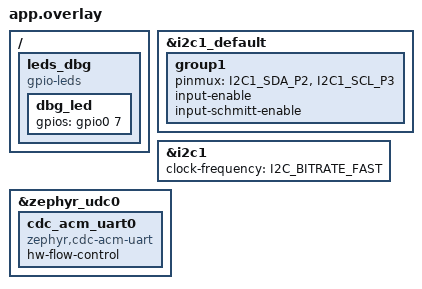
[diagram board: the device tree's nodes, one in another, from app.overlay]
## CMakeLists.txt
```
# SPDX-License-Identifier: Apache-2.0
cmake_minimum_required(VERSION 3.28.0)
find_package(Zephyr REQUIRED HINTS $ENV{ZEPHYR_BASE})
project(nfc_st25r3916)

# Function-local statics in main() run once, single-threaded: no guard runtime needed.
target_compile_options(app PRIVATE $<$<COMPILE_LANGUAGE:CXX>:-fno-threadsafe-statics>)
target_sources(app PRIVATE
  src/main.cpp
  src/Io.cpp
  src/St25r3916.cpp
  src/Nfca.cpp
  src/Ntag215.cpp
  src/Ndef.cpp
  src/IsoDep.cpp
  src/Listener.cpp
  src/Type2Tag.cpp
  src/IsoDepTarget.cpp
  src/ApduApps.cpp
  src/Cli.cpp
  src/CcidProto.cpp
  src/NfcBackend.cpp
  src/CcidService.cpp
  src/ccid_class.c
)

# USB device setup helper from the Zephyr samples (used as a template by Zephyr itself).
include(${ZEPHYR_BASE}/samples/subsys/usb/common/common.cmake)
```

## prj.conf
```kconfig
CONFIG_CPP=y
CONFIG_STD_CPP17=y
CONFIG_CPP_EXCEPTIONS=n
CONFIG_PICOLIBC=y

CONFIG_I2C=y

# USB CDC-ACM serial for the CLI (new USB device stack)
CONFIG_USB_DEVICE_STACK_NEXT=y
CONFIG_USBD_CDC_ACM_CLASS=y
CONFIG_SERIAL=y
CONFIG_UART_LINE_CTRL=y
CONFIG_CDC_ACM_SERIAL_INITIALIZE_AT_BOOT=n
CONFIG_SAMPLE_USBD_PID=0x0001
CONFIG_SAMPLE_USBD_PRODUCT="Experiment NFC (Zephyr)"
CONFIG_SAMPLE_USBD_MANUFACTURER="Experiment"

CONFIG_MAIN_STACK_SIZE=6144
CONFIG_UDC_BUF_COUNT=32
CONFIG_UDC_BUF_POOL_SIZE=4096
CONFIG_GPIO=y

# Tag emulation logs events with microsecond timestamps (the RP2350 timer runs at 1 MHz).
CONFIG_SYS_CLOCK_TICKS_PER_SEC=1000000
```

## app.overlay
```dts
/* Feather RP2350 Qwiic port: I2C1, SDA GP2, SCL GP3, 400 kHz. Built on rpi_pico2. */
#include <zephyr/dt-bindings/i2c/i2c.h>

&i2c1_default {
	group1 {
		pinmux = <I2C1_SDA_P2>, <I2C1_SCL_P3>;
		input-enable;
		input-schmitt-enable;
	};
};

&i2c1 {
	status = "okay";
	clock-frequency = <I2C_BITRATE_FAST>;
};

&zephyr_udc0 {
	cdc_acm_uart0: cdc_acm_uart0 {
		compatible = "zephyr,cdc-acm-uart";
		/* without this poll_out drops bytes when the TX buffer is full (long dumps lose lines) */
		hw-flow-control;
	};
};

/* Feather RP2350 red LED on GP7: boot/USB progress indicator. */
/ {
	leds_dbg {
		compatible = "gpio-leds";
		dbg_led: dbg_led {
			gpios = <&gpio0 7 GPIO_ACTIVE_HIGH>;
		};
	};
};
```

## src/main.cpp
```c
// Feather RP2350 + M5Stack NFC unit on Zephyr: the same serial CLI as arduino/ (copied, no Arduino dependency) (see Cli.h).
#include <zephyr/device.h>
#include <zephyr/drivers/gpio.h>
#include <zephyr/drivers/i2c.h>
#include <zephyr/drivers/uart.h>
#include <zephyr/kernel.h>

#include "CcidProto.h"
#include "CcidService.h"
#include "Cli.h"
#include "Io.h"
#include "NfcBackend.h"
#include "St25r3916.h"
#include "ZephyrTransport.h"
#include <zephyr/usb/usbd.h>  // before the extern "C" block: it pulls in C++-aware headers
extern "C" {
#include "sample_usbd.h"
}

namespace {

// Io over the CDC-ACM UART.
class UsbSerial : public nfc::Io {
 public:
  explicit UsbSerial(const struct device* uart) : uart_(uart) {}
  int available() override {
    if (peek_ < 0) {
      unsigned char c;
      if (uart_poll_in(uart_, &c) == 0) peek_ = c;
    }
    return peek_ >= 0 ? 1 : 0;
  }
  int read() override {
    if (!available()) return -1;
    int c = peek_;
    peek_ = -1;
    return c;
  }
  size_t write(const uint8_t* data, size_t len) override {
    for (size_t i = 0; i < len; i++) {
      if (data[i] == '\n') uart_poll_out(uart_, '\r');
      uart_poll_out(uart_, data[i]);
    }
    return len;
  }

 private:
  const struct device* uart_;
  int peek_ = -1;
};

}  // namespace

// Debug LED (GP7): 3 quick blinks at boot, steady on once USB is up, slow blink forever if USB init failed.
static const struct gpio_dt_spec dbgLed = GPIO_DT_SPEC_GET(DT_NODELABEL(dbg_led), gpios);

static void blink(int n, int ms) {
  for (int i = 0; i < n; i++) {
    gpio_pin_set_dt(&dbgLed, 1);
    k_msleep(ms);
    gpio_pin_set_dt(&dbgLed, 0);
    k_msleep(ms);
  }
}

int main() {
  gpio_pin_configure_dt(&dbgLed, GPIO_OUTPUT_INACTIVE);
  blink(3, 100);
  const struct device* uart = DEVICE_DT_GET(DT_NODELABEL(cdc_acm_uart0));
  const struct device* i2c = DEVICE_DT_GET(DT_NODELABEL(i2c1));

  struct usbd_context* usb = sample_usbd_init_device(NULL);
  if (usb == NULL) {
    while (true) blink(1, 1000);
  }
  // sample_usbd_init_device() only initialises: without VBUS detection the device must be enabled here.
  if (!usbd_can_detect_vbus(usb) && usbd_enable(usb) != 0) {
    while (true) blink(2, 300);
  }
  gpio_pin_set_dt(&dbgLed, 1);

  static UsbSerial serial(uart);
  static nfc::ZephyrTransport transport(i2c);
  static nfc::St25r3916 rf(transport);
  static nfc::Cli cli(serial, rf);
  static nfc::NfcBackend ccidBackend(rf);
  static nfc::ccid::Slot ccidSlot(ccidBackend);

  k_msleep(3000);  // time to attach a serial monitor
  int rc = rf.init();
  serial.printf("init: %s\n", nfc::statusName(rc));
  serial.println("type 'help' for commands");

  while (true) {
    if (rc == nfc::OK) {
      cli.poll();
      nfc::ccidService(ccidSlot, ccidBackend);
    }
    k_msleep(1);
  }
}
```

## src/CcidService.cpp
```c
#include "CcidService.h"

#include <zephyr/kernel.h>

#include "ccid_class.h"

namespace nfc {

namespace {
constexpr uint32_t POLL_MS = 300;

uint8_t rxBuf[CCID_MAX_MESSAGE + 1];
uint8_t txBuf[CCID_MAX_MESSAGE + 1];
int lastPresent = -1;  // -1 = unknown
bool notifyPending = false;
bool notifyValue = false;
uint32_t lastPoll = 0;

bool trySendNotify(bool present) {
  uint8_t msg[2];
  ccid::slotChangeMessage(present, true, msg);
  return ccid_class_notify(msg);
}
}  // namespace

void ccidService(ccid::Slot& slot, ccid::Backend& backend) {
  if (!ccid_class_is_open()) return;

  size_t n = ccid_class_poll_command(rxBuf, sizeof(rxBuf));
  if (n) {
    size_t rl = slot.handle(rxBuf, n, txBuf, sizeof(txBuf));
    if (rl) ccid_class_send(txBuf, rl);
    ccid_class_arm_out();
    return;
  }

  if (ccid_class_take_opened()) {  // host just (re)configured the device: report the current state
    lastPresent = -1;
    notifyPending = false;
  }

  if (notifyPending) {  // a notification could not be queued earlier
    if (trySendNotify(notifyValue)) notifyPending = false;
    return;
  }

  uint32_t now = k_uptime_get_32();
  if (now - lastPoll < POLL_MS) return;
  lastPoll = now;
  int st = backend.status();
  bool present = st >= 0 && st != ccid::ICC_ABSENT;
  if ((int)present != lastPresent) {
    lastPresent = present;
    notifyValue = present;
    notifyPending = !trySendNotify(present);
  }
}

}  // namespace nfc
```

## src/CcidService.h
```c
// Glue between the USB CCID class (ccid_class.c) and the CCID message layer (CcidProto, NfcBackend).
#pragma once
#include "CcidProto.h"

namespace nfc {

// Call from the main loop: answers a pending host command, and sends a slot-change notification
// when a card appears or disappears (polled every 300 ms while idle).
void ccidService(ccid::Slot& slot, ccid::Backend& backend);

}  // namespace nfc
```

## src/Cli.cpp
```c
#include "Cli.h"

#include <zephyr/kernel.h>

#include "Desfire.h"
#include "IsoDepRf.h"

#include <stdlib.h>
#include <string.h>

namespace nfc {

namespace {
const uint8_t kEmuUid[7] = {0x04, 0x11, 0x22, 0x33, 0x44, 0x55, 0x66};
// Big buffers are static to keep them off the stack.
uint8_t userBuf[USER_READ_BYTES];
uint8_t dumpBuf[DUMP_BYTES];
uint8_t firstDump[DUMP_BYTES];

// Split a line into words; double quotes group words. Modifies `line`. Returns argc.
int tokenize(char* line, char** argv, int maxArgs) {
  int argc = 0;
  char* p = line;
  while (*p && argc < maxArgs) {
    while (*p == ' ' || *p == '\t') p++;
    if (!*p) break;
    if (*p == '"') {
      argv[argc++] = ++p;
      while (*p && *p != '"') p++;
    } else {
      argv[argc++] = p;
      while (*p && *p != ' ' && *p != '\t') p++;
    }
    if (*p) *p++ = 0;
  }
  return argc;
}

int hexNibble(char c) {
  if (c >= '0' && c <= '9') return c - '0';
  if (c >= 'a' && c <= 'f') return c - 'a' + 10;
  if (c >= 'A' && c <= 'F') return c - 'A' + 10;
  return -1;
}

bool parseHex4(const char* s, uint8_t out[4]) {
  if (strlen(s) != 8) return false;
  for (int i = 0; i < 4; i++) {
    int hi = hexNibble(s[2 * i]), lo = hexNibble(s[2 * i + 1]);
    if (hi < 0 || lo < 0) return false;
    out[i] = (hi << 4) | lo;
  }
  return true;
}
}  // namespace

Cli::Cli(Io& io, St25r3916& rf)
    : io_(io), rf_(rf), tag_(rf), emuTag_(kEmuUid), t4Target_(t4App_), sniffTarget_(sniffApp_), listener_(rf, emuTag_) {}

void Cli::poll() {
  while (io_.available()) {
    char c = io_.read();
    if (c == '\r' || c == '\n') {
      if (len_ > 0) {
        line_[len_] = 0;
        len_ = 0;
        run(line_);
      }
    } else if (len_ < LINE_MAX - 1) {
      line_[len_++] = c;
    }
  }
}

void Cli::help() {
  io_.println("commands: chip | detect | dump | read-ndef | write-ndef [--text T] [--lang L] [--uri U] |");
  io_.println("          write-page <page> <8 hex> [--force] | ident | desfire | cycles [N] | emulate [S] [t2|t4|sniff] | emu-dump | help");
}

int Cli::select(Card& card) { return selectCard(rf_, card); }

void Cli::run(char* line) {
  char* argv[ARGV_MAX];
  int argc = tokenize(line, argv, ARGV_MAX);
  if (argc == 0) return;
  const char* cmd = argv[0];
  int rc;
  if (!strcmp(cmd, "chip")) rc = cmdChip();
  else if (!strcmp(cmd, "detect")) rc = cmdDetect();
  else if (!strcmp(cmd, "dump")) rc = cmdDump();
  else if (!strcmp(cmd, "read-ndef")) rc = cmdReadNdef();
  else if (!strcmp(cmd, "write-ndef")) rc = cmdWriteNdef(argc, argv);
  else if (!strcmp(cmd, "write-page")) rc = cmdWritePage(argc, argv);
  else if (!strcmp(cmd, "ident")) rc = cmdIdent();
  else if (!strcmp(cmd, "desfire")) rc = cmdDesfire();
  else if (!strcmp(cmd, "emulate")) rc = cmdEmulate(argc, argv);
  else if (!strcmp(cmd, "emu-dump")) rc = cmdEmuDump();
  else if (!strcmp(cmd, "cycles")) rc = cmdCycles(argc, argv);
  else if (!strcmp(cmd, "help")) { help(); rc = OK; }
  else { io_.printf("unknown command: %s\n", cmd); help(); rc = ERR_PARAM; }
  if (rc == OK) io_.println("ok");
  else io_.printf("error: %s\n", statusName(rc));
}

int Cli::cmdChip() {
  uint8_t type = 0, rev = 0;
  int rc = rf_.identify(&type, &rev);
  if (rc == OK) io_.printf("ST25R3916 present: type=0x%02X revision=%d\n", type, rev);
  return rc;
}

int Cli::cmdDetect() {
  Card card;
  int rc = select(card);
  if (rc != OK) return rc;
  char uid[32];
  uidToHex(card, uid, sizeof(uid));
  io_.printf("UID:  %s\n", uid);
  io_.printf("ATQA: %02X%02X  SAK: 0x%02X\n", card.atqa[0], card.atqa[1], card.sak);
  if (card.sak & 0x20) {  // SAK bit 6: the card speaks ISO 14443-4 and does not answer Type 2 READ
    io_.println("Type: ISO-DEP card (ISO 14443-4); try `desfire`");
    return OK;
  }
  bool is215 = false;
  rc = tag_.isNtag215(&is215);
  if (rc != OK) return rc;
  io_.println(is215 ? "Type: NTAG215" : "Type: not an NTAG215 (CC differs)");
  return OK;
}

int Cli::cmdDump() {
  Card card;
  int rc = select(card);
  if (rc != OK) return rc;
  rc = tag_.dump(dumpBuf);
  if (rc != OK) return rc;
  for (size_t page = 0; page < TOTAL_PAGES; page++) {
    const uint8_t* c = dumpBuf + page * PAGE_SIZE;
    char text[5];
    for (int i = 0; i < 4; i++) text[i] = (c[i] >= 32 && c[i] < 127) ? c[i] : '.';
    text[4] = 0;
    io_.printf("%3u  %02X %02X %02X %02X  %s\n", (unsigned)page, c[0], c[1], c[2], c[3], text);
  }
  return OK;
}

int Cli::cmdReadNdef() {
  Card card;
  int rc = select(card);
  if (rc != OK) return rc;
  ndef::Record recs[4];
  int n = tag_.readNdef(userBuf, recs, 4);
  if (n < 0) return n;
  if (n == 0) io_.println("no NDEF message");
  char text[120];
  for (int i = 0; i < n; i++) {
    ndef::describe(recs[i], text, sizeof(text));
    io_.println(text);
  }
  return OK;
}

int Cli::cmdWriteNdef(int argc, char** argv) {
  const char* text = nullptr;
  const char* lang = "en";
  const char* uri = nullptr;
  for (int i = 1; i < argc; i++) {
    if (!strcmp(argv[i], "--text") && i + 1 < argc) text = argv[++i];
    else if (!strcmp(argv[i], "--lang") && i + 1 < argc) lang = argv[++i];
    else if (!strcmp(argv[i], "--uri") && i + 1 < argc) uri = argv[++i];
    else { io_.printf("bad option: %s\n", argv[i]); return ERR_PARAM; }
  }
  if (!text && !uri) {
    io_.println("give --text and/or --uri");
    return ERR_PARAM;
  }
  static uint8_t tbuf[200], ubuf[200];
  ndef::Record recs[2];
  size_t n = 0;
  if (text && !ndef::textRecord(recs[n++], tbuf, sizeof(tbuf), text, lang)) return ERR_TOO_LARGE;
  if (uri && !ndef::uriRecord(recs[n++], ubuf, sizeof(ubuf), uri)) return ERR_TOO_LARGE;
  Card card;
  int rc = select(card);
  if (rc != OK) return rc;
  size_t written = 0;
  rc = tag_.writeNdef(recs, n, &written);
  if (rc != OK) return rc;
  io_.printf("wrote %u page(s)\n", (unsigned)written);
  return OK;
}

int Cli::cmdWritePage(int argc, char** argv) {
  bool force = false;
  const char* pageArg = nullptr;
  const char* hexArg = nullptr;
  for (int i = 1; i < argc; i++) {
    if (!strcmp(argv[i], "--force")) force = true;
    else if (!pageArg) pageArg = argv[i];
    else if (!hexArg) hexArg = argv[i];
    else return ERR_PARAM;
  }
  uint8_t data[4];
  if (!pageArg || !hexArg || !parseHex4(hexArg, data)) {
    io_.println("usage: write-page <page> <8 hex digits> [--force]");
    return ERR_PARAM;
  }
  int page = atoi(pageArg);
  if (page < 0 || page > 255) return ERR_PARAM;
  Card card;
  int rc = select(card);
  if (rc != OK) return rc;
  rc = tag_.writePage((uint8_t)page, data, force);
  if (rc != OK) return rc;
  io_.printf("page %d = %02X%02X%02X%02X (verified where readable)\n", page, data[0], data[1],
             data[2], data[3]);
  return OK;
}

int Cli::cmdIdent() {
  Card card;
  int rc = select(card);
  if (rc != OK) return rc;
  uint8_t v[8], sig[32], cnt[3];
  size_t n = 0;
  rc = tag_.identCmd(Ident::Version, 0, v, &n);
  if (rc != OK) return rc;
  io_.print("Version:");
  for (size_t i = 0; i < n; i++) io_.printf("%s%02X", i ? " " : " ", v[i]);
  io_.println();
  io_.printf("Type: %s\n", ntagTypeName(v, n));
  rc = tag_.identCmd(Ident::Signature, 0x00, sig, &n);
  if (rc != OK) return rc;
  io_.print("Signature: ");
  for (size_t i = 0; i < n; i++) io_.printf("%02X", sig[i]);
  io_.println();
  rc = tag_.identCmd(Ident::Counter, 0x02, cnt, &n);
  uint32_t value = 0;
  if (rc == OK && counterValue(cnt, n, &value)) io_.printf("Counter: %lu\n", (unsigned long)value);
  else if (rc == ERR_REFUSED) io_.println("Counter: not readable (NAK)");
  else return rc == OK ? ERR_BAD_RESPONSE : rc;
  return OK;
}

static void printHex(Io& io, const uint8_t* b, size_t n, char sep) {
  for (size_t i = 0; i < n; i++) {
    if (i && sep) io.print(sep);
    io.printf("%02X", b[i]);
  }
}

// ISO-DEP plus DESFire GET_VERSION and GET_APPLICATION_IDS: what the card reveals without keys.
int Cli::cmdDesfire() {
  Card card;
  int rc = select(card);
  if (rc != OK) return rc;
  char uid[32];
  uidToHex(card, uid, sizeof(uid));
  io_.printf("UID:  %s\n", uid);
  io_.printf("ATQA: %02X%02X  SAK: 0x%02X\n", card.atqa[0], card.atqa[1], card.sak);
  if (!(card.sak & 0x20)) return ERR_REFUSED;  // not an ISO-DEP card

  RfIsoDepLink link(rf_);
  IsoDep dep(link);
  rc = dep.activate();
  if (rc != OK) return rc;
  io_.print("ATS:  ");
  printHex(io_, dep.ats(), dep.atsLen(), ' ');
  io_.println();

  uint8_t v[28], aids[126];
  size_t vn = 0, an = 0;
  uint8_t sw1 = 0, sw2 = 0, asw1 = 0, asw2 = 0;
  rc = desfireCommand(dep, 0x60, v, sizeof(v), &vn, &sw1, &sw2);
  if (rc == OK) rc = desfireCommand(dep, 0x6A, aids, sizeof(aids), &an, &asw1, &asw2);
  dep.deselect();
  if (rc != OK) return rc;
  if (vn >= 28) {
    unsigned long storage = (v[5] & 1) == 0 ? 1UL << (v[5] >> 1) : 0;
    io_.printf("Version: HW %u.%u SW %u.%u vendor 0x%02X type 0x%02X storage %lu bytes\n", v[3], v[4], v[10],
               v[11], v[0], v[1], storage);
    io_.print("Card UID: ");
    printHex(io_, v + 14, 7, ':');
    io_.printf("  production week %02X year %02X\n", v[26], v[27]);
  }
  io_.printf("GET_VERSION status: %02X %02X\n", sw1, sw2);
  io_.printf("GET_APPLICATION_IDS status: %02X %02X\n", asw1, asw2);
  for (size_t i = 0; i + 3 <= an; i += 3) io_.printf("  AID %02X %02X %02X\n", aids[i], aids[i + 1], aids[i + 2]);
  return OK;
}

int Cli::cmdCycles(int argc, char** argv) {
  int n = argc > 1 ? atoi(argv[1]) : 50;
  if (n < 1 || n > 1000) return ERR_PARAM;
  int ok = 0, mismatches = 0, errors = 0;
  int lastErr = OK;
  uint32_t total = 0, worst = 0;
  bool haveFirst = false;
  for (int i = 0; i < n; i++) {
    uint32_t t0 = k_uptime_get_32();
    Card card;
    int rc = select(card);  // no field reset here: the retry inside selectCard handles a stuck tag
    if (rc == OK) rc = tag_.dump(dumpBuf);
    if (rc != OK) {
      errors++;
      lastErr = rc;
      continue;
    }
    if (!haveFirst) {
      memcpy(firstDump, dumpBuf, DUMP_BYTES);
      haveFirst = true;
    } else if (memcmp(firstDump, dumpBuf, DUMP_BYTES) != 0) {
      mismatches++;
      continue;
    }
    ok++;
    uint32_t dt = k_uptime_get_32() - t0;
    total += dt;
    if (dt > worst) worst = dt;
  }
  io_.printf("%d/%d cycles OK", ok, n);
  if (ok) io_.printf("; per cycle avg %u ms, max %u ms", (unsigned)(total / ok), (unsigned)worst);
  io_.println();
  if (mismatches) io_.printf("  %d dump mismatch(es)\n", mismatches);
  if (errors) io_.printf("  %d error(s), last: %s\n", errors, statusName(lastErr));
  return ok == n ? OK : ERR_BAD_RESPONSE;
}

// Act as a tag. No serial output while it runs: a reader gives a tag about 5 ms to answer.
int Cli::cmdEmulate(int argc, char** argv) {
  int seconds = 30;
  EmuMode mode = EMU_T2;
  for (int i = 1; i < argc; i++) {
    if (!strcmp(argv[i], "t2")) mode = EMU_T2;
    else if (!strcmp(argv[i], "t4")) mode = EMU_T4;
    else if (!strcmp(argv[i], "sniff")) mode = EMU_SNIFF;
    else seconds = atoi(argv[i]);
  }
  if (seconds < 1 || seconds > 600) return ERR_PARAM;
  uint8_t sak = 0x00;
  const char* what = "an NTAG215";
  if (mode == EMU_T2) {
    listener_.setTarget(emuTag_);
  } else if (mode == EMU_T4) {
    listener_.setTarget(t4Target_);
    sak = 0x20;  // ISO-DEP: the reader sends RATS
    what = "a Type 4 NDEF tag";
  } else {
    listener_.setTarget(sniffTarget_);
    sniffApp_.clear();
    sak = 0x20;
    what = "an ISO-DEP card that logs every APDU";
  }
  int rc = listener_.start(kEmuUid, 0x0044, sak);
  if (rc != OK) return rc;
  emuMode_ = mode;
  io_.printf("emulating %s, UID 04112233445566, for %d s: hold the phone to the unit (any byte ends it)\n", what,
             seconds);
  uint32_t t0 = k_uptime_get_32();
  uint32_t spins = 0;
  while (k_uptime_get_32() - t0 < (uint32_t)seconds * 1000) {
    listener_.poll();
    if ((++spins & 0x3F) == 0 && io_.available()) {  // any byte on the serial port ends it
      io_.read();
      break;
    }
  }
  rc = listener_.stop();
  listener_.printLog(io_);
  io_.printf("fields seen: %u, frames answered: %u", (unsigned)listener_.fieldCount(), (unsigned)listener_.frameCount());
  if (mode == EMU_T2) io_.printf(", tag writes: %u", (unsigned)emuTag_.writeCount());
  if (mode == EMU_T4) io_.printf(", NDEF file updates: %u", (unsigned)t4App_.updateCount());
  if (mode == EMU_SNIFF) io_.printf(", APDUs: %u, sessions: %u", (unsigned)sniffApp_.apduCount(), (unsigned)sniffApp_.sessionCount());
  io_.println();
  return rc;
}

// What the last `emulate` run captured: the NTAG215 memory in the format of `dump` (t2), the NDEF
// file (t4) or every APDU in full (sniff).
int Cli::cmdEmuDump() {
  if (emuMode_ == EMU_SNIFF) {
    dumpApdus();
    return OK;
  }
  const uint8_t* mem;
  size_t total;
  const uint8_t* msg = nullptr;
  size_t msgLen = 0;
  if (emuMode_ == EMU_T4) {
    const uint8_t* f = t4App_.ndefFile();
    size_t nlen = (size_t)f[0] << 8 | f[1];
    io_.printf("NDEF file: NLEN = %u, %u update(s)\n", (unsigned)nlen, (unsigned)t4App_.updateCount());
    if (nlen == 0 || nlen > Type4NdefApp::NDEF_FILE_SIZE - 2) {
      io_.println("no NDEF message");
      return OK;
    }
    for (size_t i = 0; i < nlen + 2; i += 16) {
      io_.printf("%04X ", (unsigned)i);
      for (size_t j = i; j < i + 16 && j < nlen + 2; j++) io_.printf(" %02X", f[j]);
      io_.println();
    }
    msg = f + 2;
    msgLen = nlen;
  } else {
    mem = emuTag_.memory();
    total = Type2Tag::PAGES;
    for (size_t page = 0; page < total; page++) {
      const uint8_t* c = mem + page * 4;
      char text[5];
      for (int i = 0; i < 4; i++) text[i] = (c[i] >= 32 && c[i] < 127) ? c[i] : '.';
      text[4] = 0;
      io_.printf("%3u  %02X %02X %02X %02X  %s%s\n", (unsigned)page, c[0], c[1], c[2], c[3], text,
                 emuTag_.changed(page) ? "  (written)" : "");
    }
    if (!ndef::findMessage(mem + 16, Type2Tag::BYTES - 16, &msg, &msgLen) || msgLen == 0) {
      io_.println("no NDEF message");
      return OK;
    }
  }
  ndef::Record recs[4];
  int n = ndef::decodeMessage(msg, msgLen, recs, 4);
  if (n < 0) return ERR_NDEF;
  char text[120];
  for (int i = 0; i < n; i++) {
    ndef::describe(recs[i], text, sizeof(text));
    io_.println(text);
  }
  return OK;
}

// "C> <hex>" for a command the reader sent, "R> <hex>" for our answer, one APDU per line.
void Cli::dumpApdus() {
  const uint8_t* p = sniffApp_.capture();
  const uint8_t* end = p + sniffApp_.captureSize();
  io_.printf("APDUs captured: %u in %u session(s)%s\n", (unsigned)sniffApp_.apduCount(),
             (unsigned)sniffApp_.sessionCount(), sniffApp_.full() ? " (capture buffer full, later APDUs lost)" : "");
  while (p + 3 <= end) {
    size_t len = (size_t)p[1] << 8 | p[2];
    io_.print(p[0] == 1 ? "C>" : "R>");
    for (size_t i = 0; i < len; i++) io_.printf(" %02X", p[3 + i]);
    io_.println();
    p += 3 + len;
  }
}

}  // namespace nfc
```

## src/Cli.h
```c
// Serial command interface mirroring python/nfc/cli.py. One command per line:
//   chip | detect | dump | read-ndef
//   write-ndef [--text "..."] [--lang en] [--uri https://...]
//   write-page <page> <8 hex digits> [--force]
//   cycles [N]      N x (select + full dump, compared with the first dump); default 50
//   emulate [S] [t2|t4|sniff]   act as an NFC-A tag (UID 04112233445566) for S seconds (default 30)
//                   or until any byte arrives on the serial port: t2 = NTAG215 (default), t4 = NFC Forum
//                   Type 4 NDEF tag (ISO-DEP), sniff = ISO-DEP card that logs every APDU and answers 90 00,
//                   then print the event log and the memory the reader wrote; emu-dump prints it again
//   help
// Every command ends with a line "ok" or "error: <reason>", so scripts know when it is done.
#pragma once
#include "Io.h"

#include "ApduApps.h"
#include "IsoDepTarget.h"
#include "Listener.h"
#include "Ntag215.h"
#include "St25r3916.h"
#include "Type2Tag.h"

namespace nfc {

class Cli {
 public:
  Cli(Io& io, St25r3916& rf);
  void poll();  // call from loop(): reads available characters, runs a command per complete line

 private:
  static constexpr size_t LINE_MAX = 200;
  static constexpr size_t ARGV_MAX = 10;

  void run(char* line);
  int cmdChip();
  int cmdDetect();
  int cmdDump();
  int cmdReadNdef();
  int cmdWriteNdef(int argc, char** argv);
  int cmdWritePage(int argc, char** argv);
  int cmdIdent();
  int cmdDesfire();
  int cmdCycles(int argc, char** argv);
  int cmdEmulate(int argc, char** argv);
  int cmdEmuDump();
  void dumpApdus();
  void help();
  int select(Card& card);

  Io& io_;
  St25r3916& rf_;
  Ntag215 tag_;
  Type2Tag emuTag_;
  Type4NdefApp t4App_;
  IsoDepTarget t4Target_;
  SniffApp sniffApp_;
  IsoDepTarget sniffTarget_;
  Listener listener_;
  enum EmuMode : uint8_t { EMU_NONE, EMU_T2, EMU_T4, EMU_SNIFF } emuMode_ = EMU_NONE;
  char line_[LINE_MAX];
  size_t len_ = 0;
};

}  // namespace nfc
```

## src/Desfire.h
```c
// DESFire native commands wrapped in ISO 7816 APDUs (90 INS 00 00 00), over an activated IsoDep.
// No hardware dependency (host-tested).
#pragma once
#include <string.h>

#include "IsoDep.h"

namespace nfc {

// Runs one command and follows "additional frame" replies (SW 91 AF, sent again as 90 AF 00 00 00).
// Appends the data of all frames to `out` and returns the final SW1 SW2.
inline int desfireCommand(IsoDep& dep, uint8_t ins, uint8_t* out, size_t cap, size_t* outLen,
                          uint8_t* sw1, uint8_t* sw2) {
  *outLen = 0;
  for (int frames = 0; frames < 32; frames++) {
    const uint8_t apdu[5] = {0x90, ins, 0x00, 0x00, 0x00};
    uint8_t rx[260];
    size_t n = 0;
    int rc = dep.transceive(apdu, sizeof(apdu), rx, sizeof(rx), &n);
    if (rc != OK) return rc;
    if (n < 2) return ERR_PROTOCOL;
    if (*outLen + (n - 2) > cap) return ERR_PARAM;
    memcpy(out + *outLen, rx, n - 2);
    *outLen += n - 2;
    *sw1 = rx[n - 2];
    *sw2 = rx[n - 1];
    if (!(*sw1 == 0x91 && *sw2 == 0xAF)) return OK;
    ins = 0xAF;
  }
  return ERR_PROTOCOL;  // a card that never stops asking for more
}

}  // namespace nfc
```

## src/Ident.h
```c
// NTAG identification helpers, no hardware dependency (host-tested).
// Commands: GET_VERSION 0x60, READ_SIG 0x3C 0x00, READ_CNT 0x39 0x02 (NTAG21x datasheet 10.1, 10.8, 10.6).
#pragma once
#include <stddef.h>
#include <stdint.h>

namespace nfc {

enum class Ident : uint8_t { Version = 0x60, Signature = 0x3C, Counter = 0x39 };

// Family name from a GET_VERSION reply (datasheet Table 28).
inline const char* ntagTypeName(const uint8_t* v, size_t len) {
  if (len < 8) return "unknown";
  if (v[1] != 0x04) return "unknown";
  if (v[2] != 0x04) return "NXP, not an NTAG";
  switch (v[6]) {
    case 0x0F: return "NTAG213 (NXP)";
    case 0x11: return "NTAG215 (NXP)";
    case 0x13: return "NTAG216 (NXP)";
    default: return "NTAG, unknown size (NXP)";
  }
}

// READ_CNT returns the 24-bit counter, low byte first.
inline bool counterValue(const uint8_t* b, size_t len, uint32_t* out) {
  if (len != 3) return false;
  *out = (uint32_t)b[0] | (uint32_t)b[1] << 8 | (uint32_t)b[2] << 16;
  return true;
}

// Meaning of the 4-bit NAK a tag sends after a refused WRITE (datasheet Table 23).
inline const char* nakText(uint8_t code) {
  switch (code) {
    case 0x0: return "tag refused the write: invalid argument (bad page address)";
    case 0x1: return "tag refused the write: parity or CRC error in the command";
    case 0x4: return "tag refused the write: authentication counter overflow";
    case 0x5: return "tag refused the write: EEPROM write error";
    default: return "tag refused the write: unknown NAK code";
  }
}

}  // namespace nfc
```

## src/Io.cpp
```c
#include "Io.h"

#include <stdio.h>

namespace nfc {

int Io::printf(const char* fmt, ...) {
  char buf[256];
  va_list ap;
  va_start(ap, fmt);
  int n = vsnprintf(buf, sizeof(buf), fmt, ap);
  va_end(ap);
  if (n > 0) write((const uint8_t*)buf, n < (int)sizeof(buf) ? n : sizeof(buf) - 1);
  return n;
}

}  // namespace nfc
```

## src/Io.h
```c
// Byte stream the CLI talks to (here: the USB CDC-ACM serial port).
#pragma once
#include <stdarg.h>
#include <stddef.h>
#include <stdint.h>
#include <string.h>

namespace nfc {

class Io {
 public:
  virtual ~Io() {}
  virtual int available() = 0;  // 1 if a byte can be read, else 0
  virtual int read() = 0;       // next byte or -1
  virtual size_t write(const uint8_t* data, size_t len) = 0;

  size_t print(const char* s) { return write((const uint8_t*)s, strlen(s)); }
  size_t print(char c) { return write((const uint8_t*)&c, 1); }
  size_t println(const char* s = "") {
    size_t n = print(s);
    return n + write((const uint8_t*)"\n", 1);
  }
  int printf(const char* fmt, ...) __attribute__((format(printf, 2, 3)));
};

}  // namespace nfc
```

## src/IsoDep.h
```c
// ISO-DEP (ISO/IEC 14443-4) block protocol for the reader side: RATS/ATS, I-block framing with the
// block-number toggle, chaining in both directions, waiting-time extension, retries and deselect.
//
// Port of the ISO-DEP layer in embassy-rs/rnfc (MIT or Apache-2.0), checked with the same
// ISO 14443-4 Annex B scenarios (test/test_isodep.cpp). No hardware dependency: the
// frames go through an IsoDepLink.
#pragma once
#include <stddef.h>
#include <stdint.h>

#include "St25r3916.h"  // status codes only

namespace nfc {

// One ISO 14443-A frame exchange. The link adds CRC_A when sending and checks and strips it on
// receive. Timeouts are in carrier clocks (1/13.56 MHz). Return ERR_TIMEOUT, ERR_FRAME or
// ERR_COLLISION for a lost or damaged frame (the protocol retries those), another status for a
// hard failure.
class IsoDepLink {
 public:
  virtual ~IsoDepLink() {}
  virtual int transceive(const uint8_t* tx, size_t txLen, uint8_t* rx, size_t cap, size_t* rxLen,
                         uint32_t timeout1fc) = 0;
  virtual void sleepMs(uint32_t ms) = 0;
};

class IsoDep {
 public:
  static constexpr size_t ATS_MAX = 32;

  explicit IsoDep(IsoDepLink& link) : link_(link) {}

  // Sends RATS (E0 80) and reads the ATS. The card must already be selected.
  int activate();
  // One command/response exchange of any length; handles chaining and waiting-time extension.
  int transceive(const uint8_t* tx, size_t txLen, uint8_t* rx, size_t cap, size_t* rxLen);
  // S(DESELECT): ends the session, the card goes back to idle.
  int deselect();

  const uint8_t* ats() const { return ats_; }
  size_t atsLen() const { return atsLen_; }
  size_t fsc() const { return fsc_; }
  uint32_t sfgt1fc() const { return sfgt1fc_; }
  uint32_t fwt1fc() const { return fwt1fc_; }
  void setFscForTest(size_t fsc) { fsc_ = fsc; }

 private:
  IsoDepLink& link_;
  uint8_t ats_[ATS_MAX] = {};
  size_t atsLen_ = 0;
  size_t fsc_ = 32;          // largest frame the card accepts, including header and CRC
  uint32_t sfgt1fc_ = 4096;  // start-up frame guard time
  uint32_t fwt1fc_ = 65536;  // frame waiting time
  uint8_t blockNum_ = 0;
};

}  // namespace nfc
```

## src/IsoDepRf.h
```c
// IsoDepLink on the ST25R3916: frames go through St25r3916::transceive with CRC_A handled by the chip.
#pragma once
#include <zephyr/kernel.h>

#include "IsoDep.h"
#include "St25r3916.h"

namespace nfc {

class RfIsoDepLink : public IsoDepLink {
 public:
  explicit RfIsoDepLink(St25r3916& rf) : rf_(rf) {}

  int transceive(const uint8_t* tx, size_t txLen, uint8_t* rx, size_t cap, size_t* rxLen,
                 uint32_t timeout1fc) override {
    uint32_t ms = (timeout1fc + 13559) / 13560;  // carrier clocks to milliseconds, rounded up
    if (ms < 1) ms = 1;
    return rf_.transceive(tx, txLen, rx, cap, rxLen, /*txCrc=*/true, /*rxCrc=*/true, ms);
  }
  void sleepMs(uint32_t ms) override { k_msleep(ms); }

 private:
  St25r3916& rf_;
};

}  // namespace nfc
```

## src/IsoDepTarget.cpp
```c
#include "IsoDepTarget.h"

#include <string.h>

namespace nfc {

namespace {
const uint8_t kAts[] = {0x05, 0x78, 0x80, 0x80, 0x00};
}

const uint8_t* IsoDepTarget::ats(size_t* len) {
  *len = sizeof(kAts);
  return kAts;
}

void IsoDepTarget::reset() {
  activated_ = false;
  cmdLen_ = 0;
  lastLen_ = 0;
  lastBn_ = 0;
  pendingLen_ = 0;
  wtxTotal_ = wtxSent_ = 0;
  app_.reset();
}

TargetReply IsoDepTarget::handle(const uint8_t* f, size_t n, uint8_t* out, size_t cap) {
  TargetReply r;
  if (n == 0 || cap < kMaxResponse + 3) return r;

  if (f[0] == 0xE0) {  // RATS: E0 <FSDI|CID>
    if (n != 2) return r;
    reset();
    activated_ = true;
    memcpy(out, kAts, sizeof(kAts));
    r.len = sizeof(kAts);
    return r;
  }
  if (!activated_) return r;

  const uint8_t pcb = f[0];
  const uint8_t bn = pcb & 0x01;

  if ((pcb & 0xC2) == 0x02) {  // I-block (bit 2 is always 1)
    if (pcb & 0x0C) return r;  // CID or NAD present: not supported, stay silent
    const uint8_t* info = f + 1;
    size_t infoLen = n - 1;
    if (cmdLen_ + infoLen > kMaxCommand) {
      cmdLen_ = 0;
      return r;
    }
    memcpy(cmd_ + cmdLen_, info, infoLen);
    cmdLen_ += infoLen;
    if (pcb & 0x10) {  // chaining: ask for the next block
      out[0] = 0xA2 | bn;
      r.len = 1;
      return r;
    }
    size_t rl = app_.apdu(cmd_, cmdLen_, out + 1, kMaxResponse);
    cmdLen_ = 0;
    if (rl > kMaxResponse) rl = 0;
    out[0] = 0x02 | bn;
    r.len = rl + 1;
    memcpy(last_, out, r.len);
    lastLen_ = r.len;
    lastBn_ = bn;
    int wtx = app_.takeWtxRequests();
    if (wtx > 0) {  // answer later: ask the reader to wait, send the I-block after its last S(WTX) response
      memcpy(pending_, out, r.len);
      pendingLen_ = r.len;
      wtxTotal_ = wtx;
      wtxSent_ = 1;
      out[0] = 0xF2;  // S(WTX) request, WTXM = 1
      out[1] = 0x01;
      r.len = 2;
    }
    return r;
  }

  if ((pcb & 0xC2) == 0x82) {  // R-block: ACK (0xA2/0xA3) or NAK (0xB2/0xB3)
    if (pcb & 0x10) {          // NAK: repeat the last I-block, or acknowledge if we have none
      if (lastLen_ && bn == lastBn_) {
        memcpy(out, last_, lastLen_);
        r.len = lastLen_;
      } else {
        out[0] = 0xA2 | bn;
        r.len = 1;
      }
    } else if (lastLen_ && bn == lastBn_) {  // ACK for a block we already sent: repeat it
      memcpy(out, last_, lastLen_);
      r.len = lastLen_;
    }
    return r;
  }

  if ((pcb & 0xF7) == 0xF2 && pendingLen_) {  // S(WTX) response from the reader
    if (wtxSent_ < wtxTotal_) {
      wtxSent_++;
      out[0] = 0xF2;
      out[1] = 0x01;
      r.len = 2;
    } else {  // the wait is over: the delayed answer
      memcpy(out, pending_, pendingLen_);
      r.len = pendingLen_;
      pendingLen_ = 0;
    }
    return r;
  }

  if ((pcb & 0xC7) == 0xC2) {  // S-block
    if ((pcb & 0x30) == 0x00) {  // DESELECT: answer and leave the session
      out[0] = 0xC2;
      r.len = 1;
      r.halt = true;
      activated_ = false;
      cmdLen_ = 0;
      return r;
    }
  }
  return r;
}

}  // namespace nfc
```

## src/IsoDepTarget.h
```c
// ISO 14443-4 (ISO-DEP) block layer for card emulation: the PICC side of RATS/ATS, I-blocks,
// R-blocks, S(DESELECT) and chaining of received commands. No hardware, host-tested
// (test/test_isodeptarget.cpp). The application on top sees whole APDUs.
//
// Limits: no CID, no NAD, 106 kbit/s only, replies are never chained (an application must keep its
// response within kMaxResponse bytes).
#pragma once
#include <stddef.h>
#include <stdint.h>

#include "Target.h"

namespace nfc {

// An application that answers whole APDUs. Returns the response length (including SW1 SW2).
class ApduApp {
 public:
  virtual ~ApduApp() {}
  virtual size_t apdu(const uint8_t* cmd, size_t n, uint8_t* resp, size_t cap) = 0;
  virtual void reset() {}  // a new ISO-DEP session starts (RATS)
  // After apdu(): how many S(WTX) "wait longer" requests to send before the answer, for a command
  // that takes a while (a screen refresh). 0 = answer at once. Read once per command.
  virtual int takeWtxRequests() { return 0; }
};

class IsoDepTarget : public Target {
 public:
  static constexpr size_t kMaxResponse = 250;   // fits one I-block of a 256-byte frame
  static constexpr size_t kMaxCommand = 1024;   // chained commands are collected up to this size

  explicit IsoDepTarget(ApduApp& app) : app_(app) {}

  TargetReply handle(const uint8_t* frame, size_t n, uint8_t* out, size_t cap) override;
  void reset() override;

  bool activated() const { return activated_; }
  // The ATS sent in answer to RATS (TL T0 TA1 TB1 TC1): FSC 256, 106 kbit/s only, FWT about 77 ms.
  static const uint8_t* ats(size_t* len);

 private:
  ApduApp& app_;
  bool activated_ = false;
  uint8_t cmd_[kMaxCommand];
  size_t cmdLen_ = 0;
  uint8_t last_[kMaxResponse + 3];  // last I-block sent, for retransmission after an R(NAK)
  size_t lastLen_ = 0;
  uint8_t lastBn_ = 0;
  // a delayed answer: S(WTX) requests go out first, the I-block follows the last WTX response
  uint8_t pending_[kMaxResponse + 3];
  size_t pendingLen_ = 0;
  int wtxTotal_ = 0;
  int wtxSent_ = 0;
};

}  // namespace nfc
```
